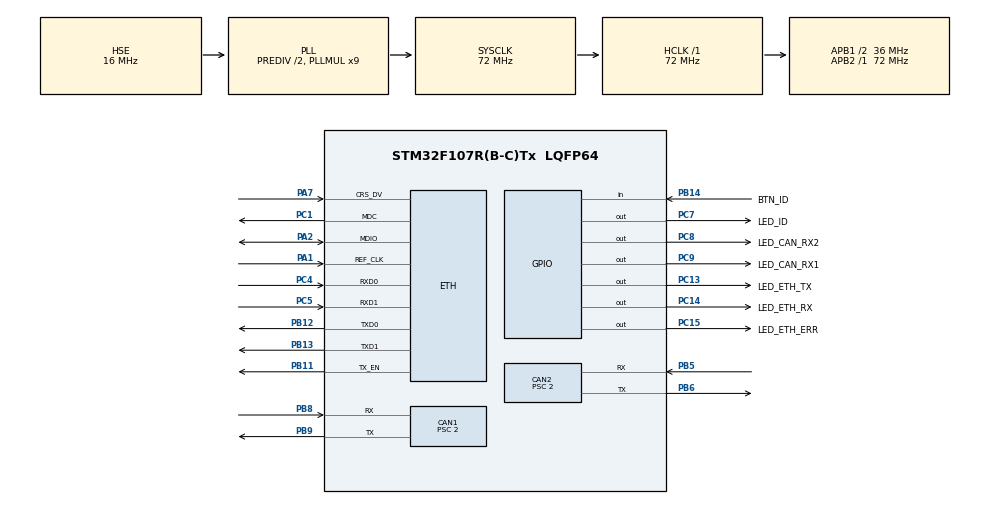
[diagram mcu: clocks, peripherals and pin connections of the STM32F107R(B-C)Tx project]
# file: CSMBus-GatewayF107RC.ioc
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CAN1.ABOM=ENABLE
CAN1.BS1=CAN_BS1_13TQ
CAN1.BS2=CAN_BS2_4TQ
CAN1.CalculateBaudRate=1000000
CAN1.CalculateTimeBit=1000
CAN1.CalculateTimeQuantum=55.55555555555556
CAN1.NART=ENABLE
CAN1.Prescaler=2
CAN2.ABOM=ENABLE
CAN2.BS1=CAN_BS1_13TQ
CAN2.BS2=CAN_BS2_4TQ
CAN2.CalculateBaudRate=1000000
CAN2.CalculateTimeBit=1000
CAN2.CalculateTimeQuantum=55.55555555555556
CAN2.NART=ENABLE
CAN2.Prescaler=2
ETH.AutoNegotiation=ETH_AUTONEGOTIATION_DISABLE
ETH.MediaInterface=ETH_MEDIA_INTERFACE_RMII
ETH.PhyAddress=0
LWIP.GATEWAY_ADDRESS=192.168.000.001
LWIP.IP_ADDRESS=192.168.000.020
LWIP.LWIP_DBG_MIN_LEVEL=LWIP_DBG_LEVEL_SEVERE
LWIP.LWIP_DHCP=0
LWIP.LWIP_TCP=0
LWIP.MEMP_NUM_PBUF=8
LWIP.MEMP_NUM_RAW_PCB=16
LWIP.MEMP_NUM_TCP_PCB=2
LWIP.MEMP_NUM_UDP_PCB=14
LWIP.MEM_SIZE=1024
LWIP.NETMASK_ADDRESS=255.255.255.000
LWIP.PBUF_POOL_SIZE=32
LWIP.Version=v2.0.3_Cube
Mcu.Family=STM32F1
Mcu.Name=STM32F107R(B-C)Tx
Mcu.Package=LQFP64
NVIC.CAN1_RX0_IRQn=true\:0\:0\:false\:false\:true\:true\:true\:true
NVIC.CAN2_RX1_IRQn=true\:0\:0\:false\:false\:true\:true\:true\:true
NVIC.PriorityGroup=NVIC_PRIORITYGROUP_4
NVIC.TIM7_IRQn=true\:0\:0\:true\:false\:true\:true\:true\:true
PA1.Mode=RMII
PA1.Signal=ETH_REF_CLK
PA13.Signal=SYS_JTMS-SWDIO
PA14.Signal=SYS_JTCK-SWCLK
PA2.Mode=RMII
PA2.Signal=ETH_MDIO
PA7.Mode=RMII
PA7.Signal=ETH_CRS_DV
PB11.Mode=RMII
PB11.Signal=ETH_TX_EN
PB12.Mode=RMII
PB12.Signal=ETH_TXD0
PB13.Mode=RMII
PB13.Signal=ETH_TXD1
PB14.GPIO_Label=BTN_ID
PB14.GPIO_PuPd=GPIO_PULLUP
PB14.Signal=GPIO_Input
PB3.Signal=SYS_TRACESWO
PB5.Mode=CAN_Activate
PB5.Signal=CAN2_RX
PB6.Mode=CAN_Activate
PB6.Signal=CAN2_TX
PB8.Mode=CAN_Activate
PB8.Signal=CAN1_RX
PB9.Mode=CAN_Activate
PB9.Signal=CAN1_TX
PC1.Mode=RMII
PC1.Signal=ETH_MDC
PC13-TAMPER-RTC.GPIO_Label=LED_ETH_TX
PC13-TAMPER-RTC.Signal=GPIO_Output
PC14-OSC32_IN.GPIO_Label=LED_ETH_RX
PC14-OSC32_IN.Signal=GPIO_Output
PC15-OSC32_OUT.GPIO_Label=LED_ETH_ERR
PC15-OSC32_OUT.Signal=GPIO_Output
PC4.Mode=RMII
PC4.Signal=ETH_RXD0
PC5.Mode=RMII
PC5.Signal=ETH_RXD1
PC7.GPIO_Label=LED_ID
PC7.Signal=GPIO_Output
PC8.GPIO_Label=LED_CAN_RX2
PC8.Signal=GPIO_Output
PC9.GPIO_Label=LED_CAN_RX1
PC9.Signal=GPIO_Output
PD0-OSC_IN.Mode=HSE-External-Oscillator
PD0-OSC_IN.Signal=RCC_OSC_IN
PD1-OSC_OUT.Mode=HSE-External-Oscillator
PD1-OSC_OUT.Signal=RCC_OSC_OUT
ProjectManager.HeapSize=0x200
ProjectManager.StackSize=0x400
ProjectManager.TargetToolchain=STM32CubeIDE
RCC.AHBFreq_Value=72000000
RCC.APB1CLKDivider=RCC_HCLK_DIV2
RCC.APB1Freq_Value=36000000
RCC.APB1TimFreq_Value=72000000
RCC.APB2Freq_Value=72000000
RCC.APB2TimFreq_Value=72000000
RCC.HCLKFreq_Value=72000000
RCC.HSEDivPLL=RCC_HSE_PREDIV_DIV2
RCC.HSE_VALUE=16000000
RCC.PLLMUL=RCC_PLL_MUL9
RCC.PLLSourceVirtual=RCC_PLLSOURCE_HSE
RCC.SYSCLKFreq_VALUE=72000000
RCC.SYSCLKSource=RCC_SYSCLKSOURCE_PLLCLK
RCC.USBFreq_Value=48000000
TIM7.AutoReloadPreload=TIM_AUTORELOAD_PRELOAD_DISABLE
TIM7.Period=1000
TIM7.Prescaler=72-1
VP_LWIP_VS_Enabled.Mode=Enabled
VP_SYS_VS_ND.Mode=No_Debug
VP_TIM7_VS_ClockSourceINT.Mode=Enable_Timer
board=custom

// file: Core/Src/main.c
/* USER CODE BEGIN Header */
/**
  ******************************************************************************
  * @file           : main.c
  * @brief          : Main program body
  ******************************************************************************
  * @attention
  *
  * Copyright (c) 2023 STMicroelectronics.
  * All rights reserved.
  *
  * This software is licensed under terms that can be found in the LICENSE file
  * in the root directory of this software component.
  * If no LICENSE file comes with this software, it is provided AS-IS.
  *
  ******************************************************************************
  */
/* USER CODE END Header */
#include "main.h"
#include "can.h"
#include "lwip.h"
#include "tim.h"
#include "gpio.h"

/* USER CODE BEGIN Includes */
#include "eth_csmbus.h"
#include "cpp_main.h"
/* USER CODE END Includes */

void SystemClock_Config(void);

/* USER CODE BEGIN 0 */
void HAL_TIM_PeriodElapsedCallback(TIM_HandleTypeDef *htim)
{
  __ECTimer_interrupt(htim);
}
/* USER CODE END 0 */

int main(void)
{

  /* MCU Configuration--------------------------------------------------------*/

  /* Reset of all peripherals, Initializes the Flash interface and the Systick. */
  HAL_Init();

  /* Configure the system clock */
  SystemClock_Config();

  /* USER CODE BEGIN SysInit */
  MX_GPIO_Init();
  ECId_init();
  /* USER CODE END SysInit */

  /* Initialize all configured peripherals */
  MX_GPIO_Init();
  MX_LWIP_Init();
  MX_CAN1_Init();
  MX_CAN2_Init();
  MX_TIM7_Init();
  /* USER CODE BEGIN 2 */
  ECLed_init();
  ECTimer_init();
  ECCan_init();
  ECBackdoor_init();
  ECCtrl_init();
  /* USER CODE END 2 */

  /* Infinite loop */
  /* USER CODE BEGIN WHILE */
  cpp_main();

  while (1)
  {
    /* USER CODE END WHILE */

  }
}

void SystemClock_Config(void)
{
  RCC_OscInitTypeDef RCC_OscInitStruct = {0};
  RCC_ClkInitTypeDef RCC_ClkInitStruct = {0};

  /** Initializes the RCC Oscillators according to the specified parameters
  * in the RCC_OscInitTypeDef structure.
  */
  RCC_OscInitStruct.OscillatorType = RCC_OSCILLATORTYPE_HSE;
  RCC_OscInitStruct.HSEState = RCC_HSE_ON;
  RCC_OscInitStruct.HSEPredivValue = RCC_HSE_PREDIV_DIV2;
  RCC_OscInitStruct.HSIState = RCC_HSI_ON;
  RCC_OscInitStruct.Prediv1Source = RCC_PREDIV1_SOURCE_HSE;
  RCC_OscInitStruct.PLL.PLLState = RCC_PLL_ON;
  RCC_OscInitStruct.PLL.PLLSource = RCC_PLLSOURCE_HSE;
  RCC_OscInitStruct.PLL.PLLMUL = RCC_PLL_MUL9;
  RCC_OscInitStruct.PLL2.PLL2State = RCC_PLL_NONE;
  if (HAL_RCC_OscConfig(&RCC_OscInitStruct) != HAL_OK)
  {
    Error_Handler();
  }

  /** Initializes the CPU, AHB and APB buses clocks
  */
  RCC_ClkInitStruct.ClockType = RCC_CLOCKTYPE_HCLK|RCC_CLOCKTYPE_SYSCLK
                              |RCC_CLOCKTYPE_PCLK1|RCC_CLOCKTYPE_PCLK2;
  RCC_ClkInitStruct.SYSCLKSource = RCC_SYSCLKSOURCE_PLLCLK;
  RCC_ClkInitStruct.AHBCLKDivider = RCC_SYSCLK_DIV1;
  RCC_ClkInitStruct.APB1CLKDivider = RCC_HCLK_DIV2;
  RCC_ClkInitStruct.APB2CLKDivider = RCC_HCLK_DIV1;

  if (HAL_RCC_ClockConfig(&RCC_ClkInitStruct, FLASH_LATENCY_2) != HAL_OK)
  {
    Error_Handler();
  }

  /** Configure the Systick interrupt time
  */
  __HAL_RCC_PLLI2S_ENABLE();
}

void Error_Handler(void)
{
  __disable_irq();
  while (1)
  {
  }
}
